# ATSAMG51 register map
Vendor: Microchip Technology; Series: SAMG51; File version: 0
CPU: CM4 r0p1, little endian, MPU, FPU, 4 interrupt priority bits
Registers are 32-bit, read-write, reset 0x0 unless marked. A register's access mark holds for its fields unless they carry their own. Offsets are from the block's base; [hi:lo] are bit positions; {n}, {i} and the like mark numbered series.

## GPBR — General Purpose Backup Registers
Base 0x400E1490; register names take the prefix GPBR_
{0x0+4i} SYS_GPBR[{i}] (i=0..7) — General Purpose Backup Register 0
  [31:0] GPBR_VALUE — Value of GPBR x

## MATRIX — AHB Bus Matrix
Base 0x400E0200; register names take the prefix MATRIX_
{0x0+4i} MATRIX_MCFG[{i}] (i=0..2) — Master Configuration Register 0
  [2:0] ULBT — Undefined Length Burst Type
    0=INFINITE (No predicted end of burst is generated and therefore INCR bursts coming from this master cannot be broken.); 1=SINGLE (The undefined length burst is treated as a succession of single access allowing rearbitration at each beat of the INCR burst.); 2=FOUR_BEAT (The undefined length burst is split into a 4-beat bursts allowing rearbitration at each 4-beat burst end.); 3=EIGHT_BEAT (The undefined length burst is split into 8-beat bursts allowing rearbitration at each 8-beat burst end.); 4=SIXTEEN_BEAT (The undefined length burst is split into 16-beat bursts allowing rearbitration at each 16-beat burst end.)
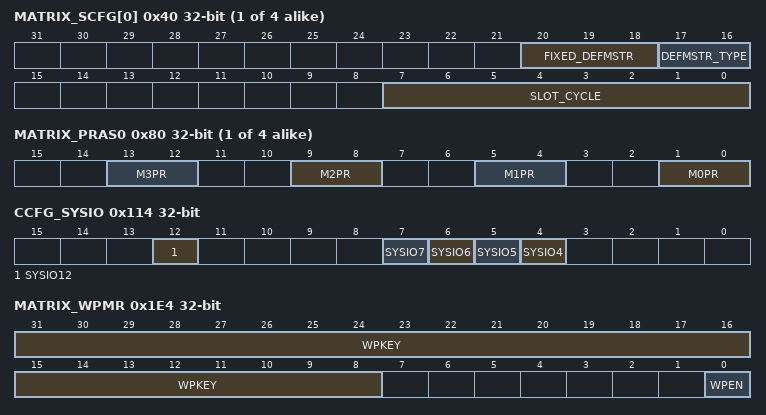
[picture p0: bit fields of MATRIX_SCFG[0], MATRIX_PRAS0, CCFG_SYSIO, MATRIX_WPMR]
{0x40+4i} MATRIX_SCFG[{i}] (i=0..3) — Slave Configuration Register 0
  [20:18] FIXED_DEFMSTR — Fixed Default Master
  [17:16] DEFMSTR_TYPE — Default Master Type
    0=NO_DEFAULT (At the end of current slave access, if no other master request is pending, the slave is disconnected from all masters.This results in having a one cycle latency for the first access of a burst transfer or for a single access.); 1=LAST (At the end of current slave access, if no other master request is pending, the slave stays connected to the last master having accessed it.This results in not having the one cycle latency when the last master tries to access the slave again.); 2=FIXED (At the end of the current slave access, if no other master request is pending, the slave connects to the fixed master the number that has been written in the FIXED_DEFMSTR field.This results in not having the one cycle latency when the fixed master tries to access the slave again.)
  [7:0] SLOT_CYCLE — Maximum Number of Allowed Cycles for a Burst
{0x80+8i} MATRIX_PRAS{i} (i=0..3) — Priority Register A for Slave {i}
  [4n+1:4n] M{n}PR (n=0..3) — Master {n} Priority
0x114 CCFG_SYSIO — System I/O Configuration Register
  [12] SYSIO12 — PB12 or ERASE Assignment
  [7] SYSIO7 — PB7 or TCK/SWCLK Assignment
  [6] SYSIO6 — PB6 or TMS/SWDIO Assignment
  [5] SYSIO5 — PB5 or TDO/TRACESWO Assignment
  [4] SYSIO4 — PB4 or TDI Assignment
0x1E4 MATRIX_WPMR — Write Protection Mode Register
  [31:8] WPKEY — Write Protection Key
    0x4D4154=PASSWD (Writing any other value in this field aborts the write operation of the WPEN bit. Always reads as 0.)
  [0] WPEN — Write Protection Enable
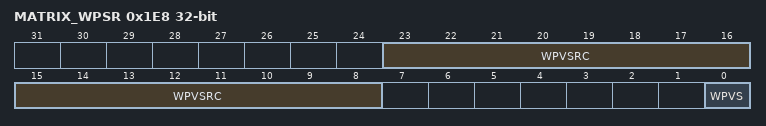
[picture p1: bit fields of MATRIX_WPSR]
0x1E8 MATRIX_WPSR ro — Write Protection Status Register
  [23:8] WPVSRC — Write Protection Violation Source
  [0] WPVS — Write Protection Violation Status

## MEM2MEM — Memory to Memory
Base 0x40028000; register names take the prefix MEM2MEM_
0x00 MEM2MEM_THR — Memory to Memory Transfer Holding Register
  [31:0] THDATA — Transfer Holding Data
0x04 MEM2MEM_MR — Memory to Memory Mode Register
  [1:0] TSIZE — Transfer Size
    0=T_8BIT (The buffer size is defined in byte.); 1=T_16BIT (The buffer size is defined in half-word (16-bit).); 2=T_32BIT (The buffer size is defined in word (32-bit). Default value.)
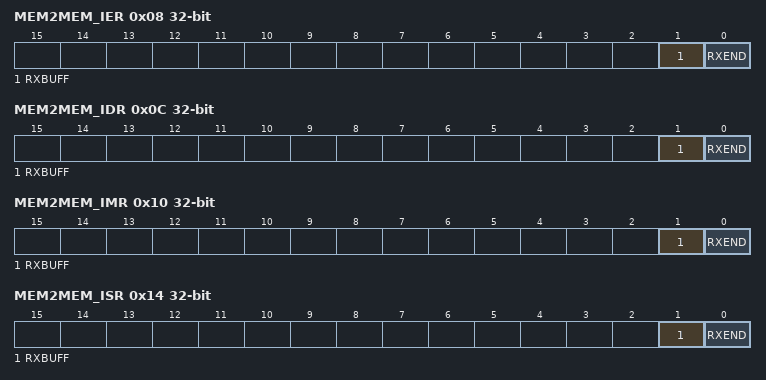
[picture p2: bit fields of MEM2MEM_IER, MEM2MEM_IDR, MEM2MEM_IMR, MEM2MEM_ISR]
0x08 MEM2MEM_IER wo — Memory to Memory Interrupt Enable Register
  [1] RXBUFF — Buffer Full Interrupt Enable
  [0] RXEND — End of Transfer Interrupt Enable
0x0C MEM2MEM_IDR wo — Memory to Memory Interrupt Disable Register
  [1] RXBUFF — Buffer Full Interrupt Disable
  [0] RXEND — End of Transfer Interrupt Disable
0x10 MEM2MEM_IMR ro — Memory to Memory Interrupt Mask Register
  [1] RXBUFF — Buffer Full Interrupt Mask
  [0] RXEND — End of Transfer Interrupt Mask
0x14 MEM2MEM_ISR ro — Memory to Memory Interrupt Status Register
  [1] RXBUFF — Buffer Full
  [0] RXEND — End of Transfer
0x100 MEM2MEM_RPR — Receive Pointer Register
  [31:0] RXPTR
0x104 MEM2MEM_RCR — Receive Counter Register
  [15:0] RXCTR
0x108 MEM2MEM_TPR — Transmit Pointer Register
  [31:0] TXPTR — Transmit Counter Register
0x10C MEM2MEM_TCR — Transmit Counter Register
  [15:0] TXCTR
0x110 MEM2MEM_RNPR — Receive Next Pointer Register
  [31:0] RXNPTR — Receive Next Pointer
0x114 MEM2MEM_RNCR — Receive Next Counter Register
  [15:0] RXNCTR — Receive Next Counter
0x118 MEM2MEM_TNPR — Transmit Next Pointer Register
  [31:0] TXNPTR — Transmit Next Pointer
0x11C MEM2MEM_TNCR — Transmit Next Counter Register
  [15:0] TXNCTR — Transmit Counter Next
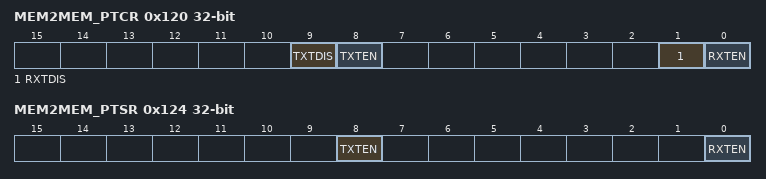
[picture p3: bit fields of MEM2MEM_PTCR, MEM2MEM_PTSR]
0x120 MEM2MEM_PTCR wo — Transfer Control Register
  [9] TXTDIS — Transmitter Transfer Disable
  [8] TXTEN — Transmitter Transfer Enable
  [1] RXTDIS — Receiver Transfer Disable
  [0] RXTEN — Receiver Transfer Enable
0x124 MEM2MEM_PTSR ro — Transfer Status Register
  [8] TXTEN — Transmitter Transfer Enable
  [0] RXTEN — Receiver Transfer Enable
